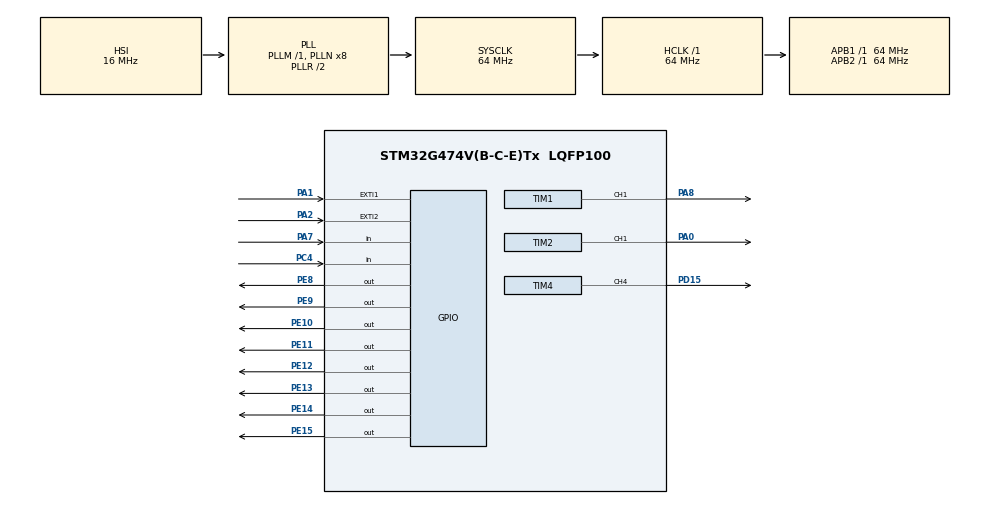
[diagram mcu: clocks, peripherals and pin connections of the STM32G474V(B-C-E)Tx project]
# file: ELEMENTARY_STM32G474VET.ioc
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Mcu.Family=STM32G4
TIM2.Channel-Output\ Compare1\ CH1=TIM_CHANNEL_1
RCC.CortexFreq_Value=64000000
RCC.SYSCLKSource=RCC_SYSCLKSOURCE_PLLCLK
ProjectManager.StackSize=0x400
NVIC.EXTI1_IRQn=true\:0\:0\:false\:false\:true\:true\:true
TIM1.Prescaler=64
RCC.HCLKFreq_Value=64000000
RCC.APB2TimFreq_Value=64000000
RCC.AHBFreq_Value=64000000
RCC.HSE_VALUE=8000000
PB3.Mode=JTAG_4_pins
RCC.ADC12Freq_Value=64000000
PA15.Mode=JTAG_4_pins
TIM2.PeriodNoDither=1000
PE13.Signal=GPIO_Output
PE9.Signal=GPIO_Output
PA14.Mode=JTAG_4_pins
NVIC.TIM2_IRQn=true\:0\:0\:false\:false\:true\:true\:true
VP_SYS_VS_DBSignals.Mode=DisableDeadBatterySignals
PA8.Signal=S_TIM1_CH1
PE10.Signal=GPIO_Output
PA0.Signal=S_TIM2_CH1
Mcu.Package=LQFP100
TIM2.Prescaler=64
TIM4.PulseNoDither_4=1000
PA15.Signal=SYS_JTDI
NVIC.EXTI2_IRQn=true\:0\:0\:false\:false\:true\:true\:true
RCC.APB1TimFreq_Value=64000000
TIM4.Channel-PWM\ Generation4\ CH4=TIM_CHANNEL_4
PA1.GPIO_ModeDefaultEXTI=GPIO_MODE_IT_RISING
PD15.Signal=S_TIM4_CH4
RCC.HSI48_VALUE=48000000
SH.S_TIM2_CH1.0=TIM2_CH1,Output Compare1 CH1
SH.S_TIM4_CH4.0=TIM4_CH4,PWM Generation4 CH4
TIM4.PeriodNoDither=1000
PC4.Signal=GPIO_Input
RCC.EXTERNAL_CLOCK_VALUE=12288000
PA13.Signal=SYS_JTMS-SWDIO
SH.S_TIM1_CH1.0=TIM1_CH1,Output Compare1 CH1
ProjectManager.TargetToolchain=STM32CubeIDE
RCC.USBFreq_Value=64000000
TIM4.Prescaler=64
PE11.Signal=GPIO_Output
RCC.LSE_VALUE=32768
PA1.Signal=GPXTI1
board=custom
RCC.VCOOutputFreq_Value=128000000
RCC.ADC345Freq_Value=64000000
RCC.APB2Freq_Value=64000000
PE14.Signal=GPIO_Output
PE15.Signal=GPIO_Output
PE8.Signal=GPIO_Output
PA13.Mode=JTAG_4_pins
Mcu.Name=STM32G474V(B-C-E)Tx
PE12.Signal=GPIO_Output
PA2.Signal=GPXTI2
PB3.Signal=SYS_JTDO-SWO
RCC.SYSCLKFreq_VALUE=64000000
PA14.Signal=SYS_JTCK-SWCLK
ProjectManager.HeapSize=0x200
TIM1.Channel-Output\ Compare1\ CH1=TIM_CHANNEL_1
RCC.HSI_VALUE=16000000
PA2.GPIO_ModeDefaultEXTI=GPIO_MODE_IT_FALLING
NVIC.TIM1_UP_TIM16_IRQn=true\:0\:0\:false\:false\:true\:true\:true
NVIC.PriorityGroup=NVIC_PRIORITYGROUP_4
NVIC.TIM4_IRQn=true\:0\:0\:false\:false\:true\:true\:true
RCC.APB1Freq_Value=64000000
TIM1.PeriodNoDither=1000
PA7.Signal=GPIO_Input

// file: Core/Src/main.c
/* USER CODE BEGIN Header */
/**
  ******************************************************************************
  * @file           : main.c
  * @brief          : Main program body
  ******************************************************************************
  * @attention
  *
  * <h2><center>&copy; Copyright (c) 2022 STMicroelectronics.
  * All rights reserved.</center></h2>
  *
  * This software component is licensed by ST under BSD 3-Clause license,
  * the "License"; You may not use this file except in compliance with the
  * License. You may obtain a copy of the License at:
  *                        opensource.org/licenses/BSD-3-Clause
  *
  ******************************************************************************
  */
/* USER CODE END Header */
#include "main.h"

TIM_HandleTypeDef htim1;
TIM_HandleTypeDef htim2;
TIM_HandleTypeDef htim4;

void SystemClock_Config(void);
static void MX_GPIO_Init(void);
static void MX_TIM1_Init(void);
static void MX_TIM2_Init(void);
static void MX_TIM4_Init(void);

int main(void)
{

  /* MCU Configuration--------------------------------------------------------*/

  /* Reset of all peripherals, Initializes the Flash interface and the Systick. */
  HAL_Init();

  /* Configure the system clock */
  SystemClock_Config();

  /* Initialize all configured peripherals */
  MX_GPIO_Init();
  MX_TIM1_Init();
  MX_TIM2_Init();
  MX_TIM4_Init();
  /* USER CODE BEGIN 2 */
  HAL_TIM_Base_Start_IT(&htim1);
  HAL_TIM_Base_Start_IT(&htim2);
  HAL_TIM_PWM_Start(&htim4,TIM_CHANNEL_4);
  /* USER CODE END 2 */

  /* Infinite loop */
  /* USER CODE BEGIN WHILE */
  while (1)
  {
	  //HAL_GPIO_Write();
	  //HAL_GPIO_Read();
	  Check_LED_Example(&htim4);
    /* USER CODE END WHILE */

  }
}

void SystemClock_Config(void)
{
  RCC_OscInitTypeDef RCC_OscInitStruct = {0};
  RCC_ClkInitTypeDef RCC_ClkInitStruct = {0};

  /** Configure the main internal regulator output voltage
  */
  HAL_PWREx_ControlVoltageScaling(PWR_REGULATOR_VOLTAGE_SCALE1);
  /** Initializes the RCC Oscillators according to the specified parameters
  * in the RCC_OscInitTypeDef structure.
  */
  RCC_OscInitStruct.OscillatorType = RCC_OSCILLATORTYPE_HSI;
  RCC_OscInitStruct.HSIState = RCC_HSI_ON;
  RCC_OscInitStruct.HSICalibrationValue = RCC_HSICALIBRATION_DEFAULT;
  RCC_OscInitStruct.PLL.PLLState = RCC_PLL_ON;
  RCC_OscInitStruct.PLL.PLLSource = RCC_PLLSOURCE_HSI;
  RCC_OscInitStruct.PLL.PLLM = RCC_PLLM_DIV1;
  RCC_OscInitStruct.PLL.PLLN = 8;
  RCC_OscInitStruct.PLL.PLLP = RCC_PLLP_DIV2;
  RCC_OscInitStruct.PLL.PLLQ = RCC_PLLQ_DIV2;
  RCC_OscInitStruct.PLL.PLLR = RCC_PLLR_DIV2;
  if (HAL_RCC_OscConfig(&RCC_OscInitStruct) != HAL_OK)
  {
    Error_Handler();
  }
  /** Initializes the CPU, AHB and APB buses clocks
  */
  RCC_ClkInitStruct.ClockType = RCC_CLOCKTYPE_HCLK|RCC_CLOCKTYPE_SYSCLK
                              |RCC_CLOCKTYPE_PCLK1|RCC_CLOCKTYPE_PCLK2;
  RCC_ClkInitStruct.SYSCLKSource = RCC_SYSCLKSOURCE_PLLCLK;
  RCC_ClkInitStruct.AHBCLKDivider = RCC_SYSCLK_DIV1;
  RCC_ClkInitStruct.APB1CLKDivider = RCC_HCLK_DIV1;
  RCC_ClkInitStruct.APB2CLKDivider = RCC_HCLK_DIV1;

  if (HAL_RCC_ClockConfig(&RCC_ClkInitStruct, FLASH_LATENCY_1) != HAL_OK)
  {
    Error_Handler();
  }
}

static void MX_TIM1_Init(void)
{

  TIM_MasterConfigTypeDef sMasterConfig = {0};
  TIM_OC_InitTypeDef sConfigOC = {0};
  TIM_BreakDeadTimeConfigTypeDef sBreakDeadTimeConfig = {0};

  htim1.Instance = TIM1;
  htim1.Init.Prescaler = 64;
  htim1.Init.CounterMode = TIM_COUNTERMODE_UP;
  htim1.Init.Period = 1000;
  htim1.Init.ClockDivision = TIM_CLOCKDIVISION_DIV1;
  htim1.Init.RepetitionCounter = 0;
  htim1.Init.AutoReloadPreload = TIM_AUTORELOAD_PRELOAD_DISABLE;
  if (HAL_TIM_OC_Init(&htim1) != HAL_OK)
  {
    Error_Handler();
  }
  sMasterConfig.MasterOutputTrigger = TIM_TRGO_RESET;
  sMasterConfig.MasterOutputTrigger2 = TIM_TRGO2_RESET;
  sMasterConfig.MasterSlaveMode = TIM_MASTERSLAVEMODE_DISABLE;
  if (HAL_TIMEx_MasterConfigSynchronization(&htim1, &sMasterConfig) != HAL_OK)
  {
    Error_Handler();
  }
  sConfigOC.OCMode = TIM_OCMODE_TIMING;
  sConfigOC.Pulse = 0;
  sConfigOC.OCPolarity = TIM_OCPOLARITY_HIGH;
  sConfigOC.OCNPolarity = TIM_OCNPOLARITY_HIGH;
  sConfigOC.OCFastMode = TIM_OCFAST_DISABLE;
  sConfigOC.OCIdleState = TIM_OCIDLESTATE_RESET;
  sConfigOC.OCNIdleState = TIM_OCNIDLESTATE_RESET;
  if (HAL_TIM_OC_ConfigChannel(&htim1, &sConfigOC, TIM_CHANNEL_1) != HAL_OK)
  {
    Error_Handler();
  }
  sBreakDeadTimeConfig.OffStateRunMode = TIM_OSSR_DISABLE;
  sBreakDeadTimeConfig.OffStateIDLEMode = TIM_OSSI_DISABLE;
  sBreakDeadTimeConfig.LockLevel = TIM_LOCKLEVEL_OFF;
  sBreakDeadTimeConfig.DeadTime = 0;
  sBreakDeadTimeConfig.BreakState = TIM_BREAK_DISABLE;
  sBreakDeadTimeConfig.BreakPolarity = TIM_BREAKPOLARITY_HIGH;
  sBreakDeadTimeConfig.BreakFilter = 0;
  sBreakDeadTimeConfig.BreakAFMode = TIM_BREAK_AFMODE_INPUT;
  sBreakDeadTimeConfig.Break2State = TIM_BREAK2_DISABLE;
  sBreakDeadTimeConfig.Break2Polarity = TIM_BREAK2POLARITY_HIGH;
  sBreakDeadTimeConfig.Break2Filter = 0;
  sBreakDeadTimeConfig.Break2AFMode = TIM_BREAK_AFMODE_INPUT;
  sBreakDeadTimeConfig.AutomaticOutput = TIM_AUTOMATICOUTPUT_DISABLE;
  if (HAL_TIMEx_ConfigBreakDeadTime(&htim1, &sBreakDeadTimeConfig) != HAL_OK)
  {
    Error_Handler();
  }
  HAL_TIM_MspPostInit(&htim1);

}

static void MX_TIM2_Init(void)
{

  TIM_MasterConfigTypeDef sMasterConfig = {0};
  TIM_OC_InitTypeDef sConfigOC = {0};

  htim2.Instance = TIM2;
  htim2.Init.Prescaler = 64;
  htim2.Init.CounterMode = TIM_COUNTERMODE_UP;
  htim2.Init.Period = 1000;
  htim2.Init.ClockDivision = TIM_CLOCKDIVISION_DIV1;
  htim2.Init.AutoReloadPreload = TIM_AUTORELOAD_PRELOAD_DISABLE;
  if (HAL_TIM_OC_Init(&htim2) != HAL_OK)
  {
    Error_Handler();
  }
  sMasterConfig.MasterOutputTrigger = TIM_TRGO_RESET;
  sMasterConfig.MasterSlaveMode = TIM_MASTERSLAVEMODE_DISABLE;
  if (HAL_TIMEx_MasterConfigSynchronization(&htim2, &sMasterConfig) != HAL_OK)
  {
    Error_Handler();
  }
  sConfigOC.OCMode = TIM_OCMODE_TIMING;
  sConfigOC.Pulse = 0;
  sConfigOC.OCPolarity = TIM_OCPOLARITY_HIGH;
  sConfigOC.OCFastMode = TIM_OCFAST_DISABLE;
  if (HAL_TIM_OC_ConfigChannel(&htim2, &sConfigOC, TIM_CHANNEL_1) != HAL_OK)
  {
    Error_Handler();
  }
  HAL_TIM_MspPostInit(&htim2);

}

static void MX_TIM4_Init(void)
{

  TIM_MasterConfigTypeDef sMasterConfig = {0};
  TIM_OC_InitTypeDef sConfigOC = {0};

  htim4.Instance = TIM4;
  htim4.Init.Prescaler = 64;
  htim4.Init.CounterMode = TIM_COUNTERMODE_UP;
  htim4.Init.Period = 1000;
  htim4.Init.ClockDivision = TIM_CLOCKDIVISION_DIV1;
  htim4.Init.AutoReloadPreload = TIM_AUTORELOAD_PRELOAD_DISABLE;
  if (HAL_TIM_PWM_Init(&htim4) != HAL_OK)
  {
    Error_Handler();
  }
  sMasterConfig.MasterOutputTrigger = TIM_TRGO_RESET;
  sMasterConfig.MasterSlaveMode = TIM_MASTERSLAVEMODE_DISABLE;
  if (HAL_TIMEx_MasterConfigSynchronization(&htim4, &sMasterConfig) != HAL_OK)
  {
    Error_Handler();
  }
  sConfigOC.OCMode = TIM_OCMODE_PWM1;
  sConfigOC.Pulse = 1000;
  sConfigOC.OCPolarity = TIM_OCPOLARITY_HIGH;
  sConfigOC.OCFastMode = TIM_OCFAST_DISABLE;
  if (HAL_TIM_PWM_ConfigChannel(&htim4, &sConfigOC, TIM_CHANNEL_4) != HAL_OK)
  {
    Error_Handler();
  }
  HAL_TIM_MspPostInit(&htim4);

}

static void MX_GPIO_Init(void)
{
  GPIO_InitTypeDef GPIO_InitStruct = {0};

  /* GPIO Ports Clock Enable */
  __HAL_RCC_GPIOA_CLK_ENABLE();
  __HAL_RCC_GPIOC_CLK_ENABLE();
  __HAL_RCC_GPIOE_CLK_ENABLE();
  __HAL_RCC_GPIOD_CLK_ENABLE();
  __HAL_RCC_GPIOB_CLK_ENABLE();

  /*Configure GPIO pin Output Level */
  HAL_GPIO_WritePin(GPIOE, GPIO_PIN_8|GPIO_PIN_9|GPIO_PIN_10|GPIO_PIN_11
                          |GPIO_PIN_12|GPIO_PIN_13|GPIO_PIN_14|GPIO_PIN_15, GPIO_PIN_RESET);

  /*Configure GPIO pin : PA1 */
  GPIO_InitStruct.Pin = GPIO_PIN_1;
  GPIO_InitStruct.Mode = GPIO_MODE_IT_RISING;
  GPIO_InitStruct.Pull = GPIO_NOPULL;
  HAL_GPIO_Init(GPIOA, &GPIO_InitStruct);

  /*Configure GPIO pin : PA2 */
  GPIO_InitStruct.Pin = GPIO_PIN_2;
  GPIO_InitStruct.Mode = GPIO_MODE_IT_FALLING;
  GPIO_InitStruct.Pull = GPIO_NOPULL;
  HAL_GPIO_Init(GPIOA, &GPIO_InitStruct);

  /*Configure GPIO pin : PA7 */
  GPIO_InitStruct.Pin = GPIO_PIN_7;
  GPIO_InitStruct.Mode = GPIO_MODE_INPUT;
  GPIO_InitStruct.Pull = GPIO_NOPULL;
  HAL_GPIO_Init(GPIOA, &GPIO_InitStruct);

  /*Configure GPIO pin : PC4 */
  GPIO_InitStruct.Pin = GPIO_PIN_4;
  GPIO_InitStruct.Mode = GPIO_MODE_INPUT;
  GPIO_InitStruct.Pull = GPIO_NOPULL;
  HAL_GPIO_Init(GPIOC, &GPIO_InitStruct);

  /*Configure GPIO pins : PE8 PE9 PE10 PE11
                           PE12 PE13 PE14 PE15 */
  GPIO_InitStruct.Pin = GPIO_PIN_8|GPIO_PIN_9|GPIO_PIN_10|GPIO_PIN_11
                          |GPIO_PIN_12|GPIO_PIN_13|GPIO_PIN_14|GPIO_PIN_15;
  GPIO_InitStruct.Mode = GPIO_MODE_OUTPUT_PP;
  GPIO_InitStruct.Pull = GPIO_NOPULL;
  GPIO_InitStruct.Speed = GPIO_SPEED_FREQ_LOW;
  HAL_GPIO_Init(GPIOE, &GPIO_InitStruct);

  /* EXTI interrupt init*/
  HAL_NVIC_SetPriority(EXTI1_IRQn, 0, 0);
  HAL_NVIC_EnableIRQ(EXTI1_IRQn);

  HAL_NVIC_SetPriority(EXTI2_IRQn, 0, 0);
  HAL_NVIC_EnableIRQ(EXTI2_IRQn);

}

void Error_Handler(void)
{
  __disable_irq();
  while (1)
  {
  }
}

/************************ (C) COPYRIGHT STMicroelectronics *****END OF FILE****/
